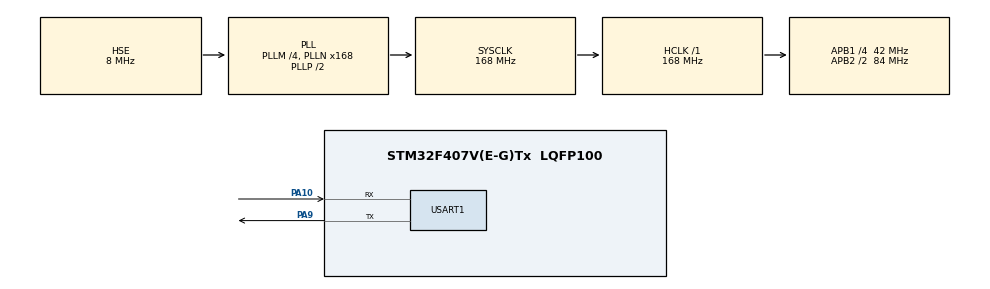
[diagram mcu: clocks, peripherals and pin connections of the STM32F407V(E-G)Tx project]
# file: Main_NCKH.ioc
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Mcu.Family=STM32F4
Mcu.Name=STM32F407V(E-G)Tx
Mcu.Package=LQFP100
NVIC.PriorityGroup=NVIC_PRIORITYGROUP_4
NVIC.TIM8_TRG_COM_TIM14_IRQn=true\:15\:0\:false\:false\:true\:false\:true\:true
NVIC.TimeBase=TIM8_TRG_COM_TIM14_IRQn
NVIC.TimeBaseIP=TIM14
NVIC.USART1_IRQn=true\:0\:0\:false\:false\:true\:true\:true\:true
PA10.Mode=Asynchronous
PA10.Signal=USART1_RX
PA13.Mode=Serial_Wire
PA13.Signal=SYS_JTMS-SWDIO
PA14.Mode=Serial_Wire
PA14.Signal=SYS_JTCK-SWCLK
PA9.Mode=Asynchronous
PA9.Signal=USART1_TX
PH0-OSC_IN.Mode=HSE-External-Oscillator
PH0-OSC_IN.Signal=RCC_OSC_IN
PH1-OSC_OUT.Mode=HSE-External-Oscillator
PH1-OSC_OUT.Signal=RCC_OSC_OUT
ProjectManager.HeapSize=0x200
ProjectManager.StackSize=0x400
ProjectManager.TargetToolchain=STM32CubeIDE
RCC.48MHZClocksFreq_Value=84000000
RCC.AHBFreq_Value=168000000
RCC.APB1CLKDivider=RCC_HCLK_DIV4
RCC.APB1Freq_Value=42000000
RCC.APB1TimFreq_Value=84000000
RCC.APB2CLKDivider=RCC_HCLK_DIV2
RCC.APB2Freq_Value=84000000
RCC.APB2TimFreq_Value=168000000
RCC.CortexFreq_Value=168000000
RCC.HCLKFreq_Value=168000000
RCC.HSE_VALUE=8000000
RCC.HSI_VALUE=16000000
RCC.LSE_VALUE=32768
RCC.PLLM=4
RCC.PLLN=168
RCC.PLLSourceVirtual=RCC_PLLSOURCE_HSE
RCC.SYSCLKFreq_VALUE=168000000
RCC.SYSCLKSource=RCC_SYSCLKSOURCE_PLLCLK
RCC.VCOOutputFreq_Value=336000000
USART1.VirtualMode=VM_ASYNC
VP_SYS_VS_tim14.Mode=TIM14
board=custom

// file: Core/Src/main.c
/* USER CODE BEGIN Header */
/**
  ******************************************************************************
  * @file           : main.c
  * @brief          : Main program body
  ******************************************************************************
  * @attention
  *
  * Copyright (c) 2025 STMicroelectronics.
  * All rights reserved.
  *
  * This software is licensed under terms that can be found in the LICENSE file
  * in the root directory of this software component.
  * If no LICENSE file comes with this software, it is provided AS-IS.
  *
  ******************************************************************************
  */
/* USER CODE END Header */
#include "main.h"

/* USER CODE BEGIN PM */
#define MAX_LED 16

/* USER CODE END PM */

UART_HandleTypeDef huart1;

/* USER CODE BEGIN PV */
typedef enum DIR_MODE{
	STOP = 0,
	FORWARD,
	BACKWARD,
	LEFT,
	RIGHT
}DIR_MODE;

DIR_MODE dir_data[MAX_LED] = {STOP};

uint8_t rx_data[MAX_LED + 2];
uint8_t tx_data[3];
uint8_t current_step;
uint8_t received = 0;
uint16_t cnt;
/* USER CODE END PV */

void SystemClock_Config(void);
static void MX_GPIO_Init(void);
static void MX_USART1_UART_Init(void);

/* USER CODE BEGIN 0 */
void prepareToSend()
{
	tx_data[0] = 0x0A;
	tx_data[1] = current_step;
	tx_data[2] = 0x1C;

	HAL_UART_Transmit(&huart1, tx_data, 18, HAL_MAX_DELAY);
}

void HAL_UART_RxCpltCallback(UART_HandleTypeDef *huart)
{
	if(huart->Instance == USART1)
	{
		if(rx_data[0] == 0x0A && rx_data[MAX_LED + 1] == 0x1C)
		{
			for(uint8_t i = 1; i < (MAX_LED+1); i++)
			{
				dir_data[i-1] = rx_data[i];
			}
			for(uint8_t i = 0; i < (MAX_LED+2); i++) rx_data[i] = 0;
			received = 1;
		}
		else
		{
			for(uint8_t i = 0; i < (MAX_LED+2); i++) rx_data[i] = 0;
		}
		HAL_UART_Receive_IT(&huart1, (uint8_t *)rx_data, (MAX_LED+2));
	}
}
/* USER CODE END 0 */

int main(void)
{

  /* MCU Configuration--------------------------------------------------------*/

  /* Reset of all peripherals, Initializes the Flash interface and the Systick. */
  HAL_Init();

  /* Configure the system clock */
  SystemClock_Config();

  /* Initialize all configured peripherals */
  MX_GPIO_Init();
  MX_USART1_UART_Init();
  /* USER CODE BEGIN 2 */
  HAL_UART_Receive_IT(&huart1, (uint8_t *)rx_data, (MAX_LED+2));
  /* USER CODE END 2 */

  /* Infinite loop */
  while (1)
  {

    /* USER CODE BEGIN 3 */
	if(received)
	{
		cnt++;
		if(cnt > 2000)
		{
			if(cnt % 2000 == 0)
			{
				current_step++;
				prepareToSend();
			}
			if(current_step == MAX_LED)
			{
				received = 0;
				current_step = 0;
				cnt = 0;
			}
		}
		HAL_Delay(1);
	}
  }
  /* USER CODE END 3 */
}

void SystemClock_Config(void)
{
  RCC_OscInitTypeDef RCC_OscInitStruct = {0};
  RCC_ClkInitTypeDef RCC_ClkInitStruct = {0};

  /** Configure the main internal regulator output voltage
  */
  __HAL_RCC_PWR_CLK_ENABLE();
  __HAL_PWR_VOLTAGESCALING_CONFIG(PWR_REGULATOR_VOLTAGE_SCALE1);

  /** Initializes the RCC Oscillators according to the specified parameters
  * in the RCC_OscInitTypeDef structure.
  */
  RCC_OscInitStruct.OscillatorType = RCC_OSCILLATORTYPE_HSE;
  RCC_OscInitStruct.HSEState = RCC_HSE_ON;
  RCC_OscInitStruct.PLL.PLLState = RCC_PLL_ON;
  RCC_OscInitStruct.PLL.PLLSource = RCC_PLLSOURCE_HSE;
  RCC_OscInitStruct.PLL.PLLM = 4;
  RCC_OscInitStruct.PLL.PLLN = 168;
  RCC_OscInitStruct.PLL.PLLP = RCC_PLLP_DIV2;
  RCC_OscInitStruct.PLL.PLLQ = 4;
  if (HAL_RCC_OscConfig(&RCC_OscInitStruct) != HAL_OK)
  {
    Error_Handler();
  }

  /** Initializes the CPU, AHB and APB buses clocks
  */
  RCC_ClkInitStruct.ClockType = RCC_CLOCKTYPE_HCLK|RCC_CLOCKTYPE_SYSCLK
                              |RCC_CLOCKTYPE_PCLK1|RCC_CLOCKTYPE_PCLK2;
  RCC_ClkInitStruct.SYSCLKSource = RCC_SYSCLKSOURCE_PLLCLK;
  RCC_ClkInitStruct.AHBCLKDivider = RCC_SYSCLK_DIV1;
  RCC_ClkInitStruct.APB1CLKDivider = RCC_HCLK_DIV4;
  RCC_ClkInitStruct.APB2CLKDivider = RCC_HCLK_DIV2;

  if (HAL_RCC_ClockConfig(&RCC_ClkInitStruct, FLASH_LATENCY_5) != HAL_OK)
  {
    Error_Handler();
  }
}

static void MX_USART1_UART_Init(void)
{

  huart1.Instance = USART1;
  huart1.Init.BaudRate = 115200;
  huart1.Init.WordLength = UART_WORDLENGTH_8B;
  huart1.Init.StopBits = UART_STOPBITS_1;
  huart1.Init.Parity = UART_PARITY_NONE;
  huart1.Init.Mode = UART_MODE_TX_RX;
  huart1.Init.HwFlowCtl = UART_HWCONTROL_NONE;
  huart1.Init.OverSampling = UART_OVERSAMPLING_16;
  if (HAL_UART_Init(&huart1) != HAL_OK)
  {
    Error_Handler();
  }

}

static void MX_GPIO_Init(void)
{

  /* GPIO Ports Clock Enable */
  __HAL_RCC_GPIOH_CLK_ENABLE();
  __HAL_RCC_GPIOA_CLK_ENABLE();

}

void HAL_TIM_PeriodElapsedCallback(TIM_HandleTypeDef *htim)
{
  if (htim->Instance == TIM14)
  {
    HAL_IncTick();
  }
}

void Error_Handler(void)
{
  __disable_irq();
  while (1)
  {
  }
}
